# nrf9230_enga_sysctrl register map
Vendor: Nordic Semiconductor; Series: nRF92; File version: 1
Registers are 32-bit, read-write, reset 0x0 unless marked. A register's access mark holds for its fields unless they carry their own. Offsets are from the block's base; [hi:lo] are bit positions; lines under a group give offsets from that group; {n}, {i} and the like mark numbered series; 'fields as' and 'values as' point back to an identical list.

## GLOBAL_EGU130 — Event generator unit
Base 0x5F92D000
{0x0+4i} TASKS_TRIGGER[{i}] (i=0..15) wo — Description collection: Trigger n for triggering the corresponding TRIGGERED[n] event
  [0] TASKS_TRIGGER — Trigger n for triggering the corresponding TRIGGERED[n] event
    1=Trigger task
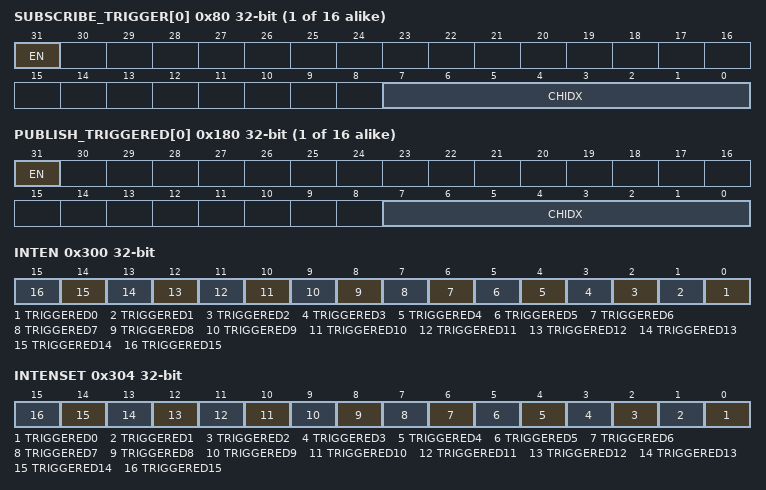
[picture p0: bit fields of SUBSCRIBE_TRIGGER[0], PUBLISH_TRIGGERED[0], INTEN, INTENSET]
{0x80+4i} SUBSCRIBE_TRIGGER[{i}] (i=0..15) — Description collection: Subscribe configuration for task TRIGGER[n]
  [31] EN
    0=Disabled (Disable subscription); 1=Enabled (Enable subscription)
  [7:0] CHIDX — DPPI channel that task TRIGGER[n] will subscribe to
{0x100+4i} EVENTS_TRIGGERED[{i}] (i=0..15) — Description collection: Event number n generated by triggering the corresponding TRIGGER[n] task
  [0] EVENTS_TRIGGERED — Event number n generated by triggering the corresponding TRIGGER[n] task
    0=NotGenerated (Event not generated); 1=Generated (Event generated)
{0x180+4i} PUBLISH_TRIGGERED[{i}] (i=0..15) — Description collection: Publish configuration for event TRIGGERED[n]
  [31] EN
    0=Disabled (Disable publishing); 1=Enabled (Enable publishing)
  [7:0] CHIDX — DPPI channel that event TRIGGERED[n] will publish to
0x300 INTEN — Enable or disable interrupt
  [all] fields
    0=Disabled; 1=Enabled
  [n] TRIGGERED{n} (n=0..15) — Enable or disable interrupt for event TRIGGERED[{n}]
0x304 INTENSET — Enable interrupt
  [all] fields
    on read: 0=Disabled (Read: Disabled); 1=Enabled (Read: Enabled) | on write: 1=Set (Enable)
  [n] TRIGGERED{n} (n=0..15) — Write '1' to enable interrupt for event TRIGGERED[{n}]
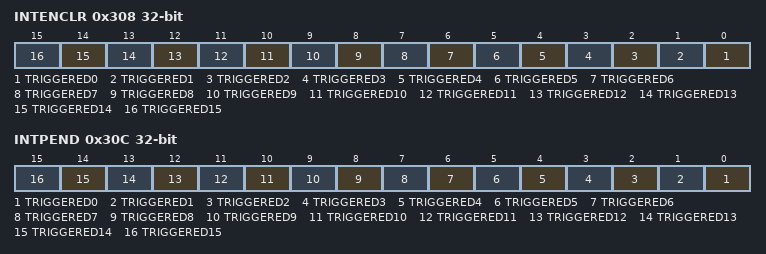
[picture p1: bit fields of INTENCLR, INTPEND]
0x308 INTENCLR — Disable interrupt
  [all] fields
    on read: 0=Disabled (Read: Disabled); 1=Enabled (Read: Enabled) | on write: 1=Clear (Disable)
  [n] TRIGGERED{n} (n=0..15) — Write '1' to disable interrupt for event TRIGGERED[{n}]
0x30C INTPEND ro — Pending interrupts
  [all] fields
    on read: 0=NotPending (Read: Not pending); 1=Pending (Read: Pending)
  [n] TRIGGERED{n} (n=0..15) — Read pending status of interrupt for event TRIGGERED[{n}]

## GLOBAL_GPIOINTERNAL — GPIO Internal
Base 0x5F939E00
0x40 LATCHCLRWAITCNT reset 0x2 — Select the number of wait cycles inserted on the bus when a LATCH register is cleared.
  [1:0] LATCHCLRWAITCNT
0x44 FORCELDETECTLOWCNT reset 0x8 — Select the number of cycles that LDETECT is forced low after clearing a LATCH register.
  [3:0] FORCELDETECTLOWCNT
0x48 RESET — Reset all GPIO registers.
  [0] RESET
    1=RESET (Trigger reset); 0=NA (No effect)
0x4C SENSECONFIGCHANGECNT reset 0x3 — Selects the number of cycles before the SENSE configuration takes effect when it is changed. Setting this register lower than the reset value can lead to unwanted LATCH set when SENSE and INPUT fields (PIN[n].CNF) are changed simultaneously.
  [2:0] SENSECONFIGCHANGECNT — Selects the number of cycles before the SENSE configuration takes effect when it is changed.
0x160 PCGC group — Unspecified
  0x00 TURNOFFAUTOCLOCKSOURCEREQ ro — No functionality
  {0x20+4j} PENALTY[{j}] (j=0..4) ro — Description collection: Penalty level for power/clock pair n
    [7:0] PENALTY — Penalty level
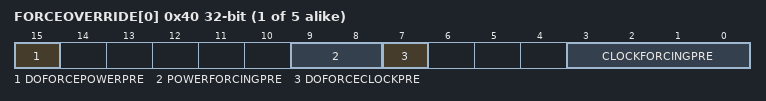
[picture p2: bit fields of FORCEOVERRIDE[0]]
  {0x40+4j} FORCEOVERRIDE[{j}] (j=0..4) ro — Description collection: Force override of power/clock pair n
    [15] DOFORCEPOWERPRE, [9:8] POWERFORCINGPRE, [7] DOFORCECLOCKPRE, [3:0] CLOCKFORCINGPRE

## OSCRFR — OSCRFR peripheral
Base 0x5F96B000
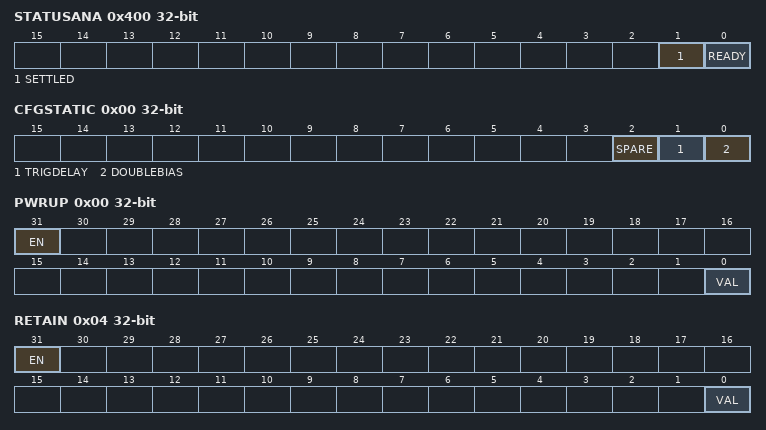
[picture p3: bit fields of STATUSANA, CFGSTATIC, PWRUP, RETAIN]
0x400 STATUSANA ro — Status of analog module output signals
  [1] SETTLED — Current value of the SETTLED signal from the analog module
  [0] READY — Current value of the READY signal from the analog module
0x410 CONFIG group — Unspecified
  0x00 CFGSTATIC — OSCRFR static CFG configuration
    [2] SPARE
    [1] TRIGDELAY — Increase TRIG signal delay
      0=Disabled; 1=Enabled
    [0] DOUBLEBIAS — Enable double bias
      0=Disabled; 1=Enabled
0x440 TRIM group — Unspecified
  0x00 OSC — Oscillation period trimming
    [2:0] VAL — Oscillation period trimming value
      0=Normal trim value; 1=The trim value is 35 percent; 2=The trim value is 154 percent; 3=The trim value is 670 percent; 4=ValNeg51 (The trim value is -54 percent); 5=ValNeg42 (The trim value is -49 percent); 6=ValNeg31 (The trim value is -37 percent); 7=ValNeg18 (The trim value is -26 percent)
  0x04 IBPSR — IBPSR current trimming
    [3:0] VAL — IBPSR current and VREF voltage trimming value
0x480 MIRROR reset 0x1 — Enable LOCK for mirrored registers
  [0] LOCK — Lock for mirrored registers
    0=Disabled (Lock disabled); 1=Enabled (Lock enabled)
0x484 MODE — Oscillator mode
  [0] MODE
    0=Normal mode - Use internal oscillator; 1=Bypass mode - Use OSC_RFR_DIG_AO_0V8 signal
0x500 OVERRIDE group — Unspecified
  0x00 PWRUP — Override the PWRUP signal to the analog module
    [31] EN — Enable the override
      0=Disabled (Override is disabled); 1=Enabled (Override is enabled)
    [0] VAL — Override value for the signal
  0x04 RETAIN — Override the RETAIN signal to the analog module
    fields as OVERRIDE.PWRUP
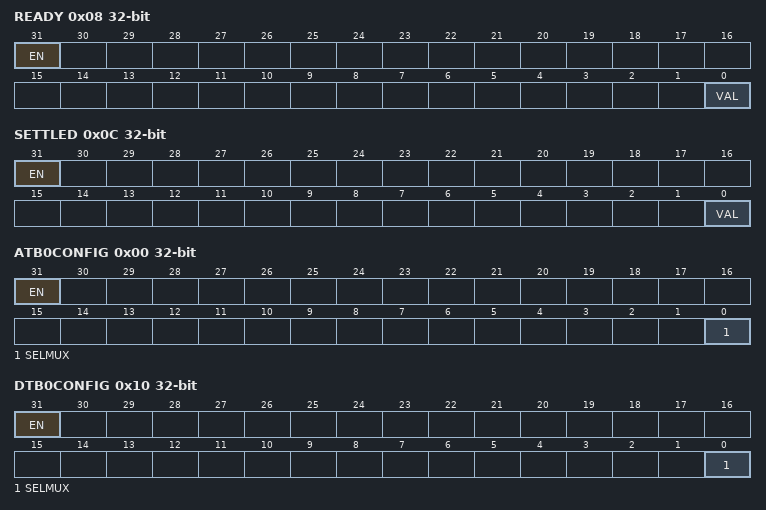
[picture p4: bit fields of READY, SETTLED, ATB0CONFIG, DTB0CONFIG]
  0x08 READY — Override the READY signal from the analog module
    [31] EN — Enable the override
      values as OVERRIDE.PWRUP.EN
    [0] VAL — Current value of the signal
  0x0C SETTLED — Override the SETTLED signal from the analog module
    fields as OVERRIDE.READY
0x600 DFT group — Unspecified
  0x00 ATB0CONFIG — Analog Test Bus 0 (ATB0) configuration
    [31] EN — Enable the analog test bus
      0=Disabled (Analog test bus is disabled); 1=Enabled (Analog test bus is enabled)
    [0] SELMUX — Select multiplexer for ATB0
      0=IBPSR4U (IBPSR_4U signal selected); 1=IBPP50N (IBPP_50N signal selected)
  0x10 DTB0CONFIG — Digital Test Bus 0 (DTB0) configuration
    [31] EN — Enable the digital test bus
      0=Disabled (Digital test bus is disabled); 1=Enabled (Digital test bus is enabled)
    [0] SELMUX — Select multiplexer for DTB0
      0=READY (READY signal selected); 1=OSC (OSC_RFR_ANA_AO_0V8 signal selected)
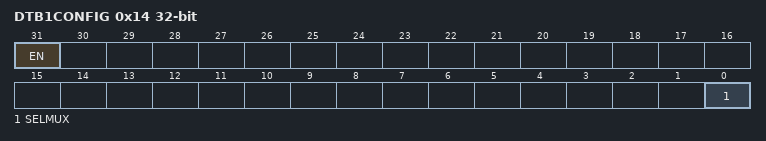
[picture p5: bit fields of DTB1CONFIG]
  0x14 DTB1CONFIG — Digital Test Bus 1 (DTB1) configuration
    [31] EN — Enable the digital test bus
      values as DFT.DTB0CONFIG.EN
    [0] SELMUX — Select multiplexer for DTB1
      0=SETTLED (SETTLED signal selected); 1=OSC (OSC_RFR_ANA_AO_0V8 signal selected)
  0x1C DTB3CONFIG — Digital Test Bus 3 (DTB3) configuration
    [27] PWRUPDELTEST — Enable the PWRUP delay test circuit
      0=Disabled (PWRUP delay test circuit is disabled); 1=Enabled (PWRUP delay test circuit is enabled)
  0x30 TCFG — Test mode configuration
    [0] BIASCURRENT — Enable continuous mode for measuring bias current over ATB
      0=Disabled; 1=Enabled

## VDETIO — VDETIO peripheral
Base 0x5F974000
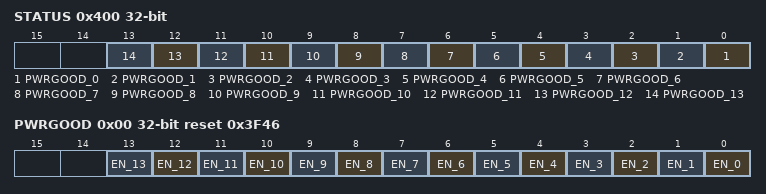
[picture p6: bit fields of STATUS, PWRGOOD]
0x400 STATUS ro — Voltage detector status
  [all] fields
    0=AboveThr (Power good detector detected voltage above threshold level); 1=BelowThr (Power good detector detected voltage below threshold level)
  [n] PWRGOOD_{n} (n=0..13) — Power good detector status for port [{n}]
0x410 CONFIG group — Unspecified
  0x00 PWRGOOD reset 0x3F46 — Power good detector configuration
    [all] fields
      0=Disabled (IO voltage detector is disabled); 1=Enabled (IO voltage detector is enabled)
    [n] EN_{n} (n=0..13) — Enable the power good detector for port [{n}]

## VSPOWERC — VSPOWERC peripheral
Base 0x5F977000
{0x410+8i} CONFIG[{i}] (i=0..1) group — Unspecified
  0x00 PWRSRC — Description cluster: Power source select for dual power switch domain [n]
    [0] SRC — Selecting between VS and AO power
      0=SelVS (Voltage scaled VDD_VS_0V8); 1=SelAO (Always-on VDD_AO_0V8)
  0x04 OVERLAP — Description cluster: Configuration of switch control overlap time for dual power switch domain [n]
    [3:0] VAL — Overlap time, both power requests active
{0x500+4i} OVERRIDE[{i}] (i=0..1) group — Unspecified
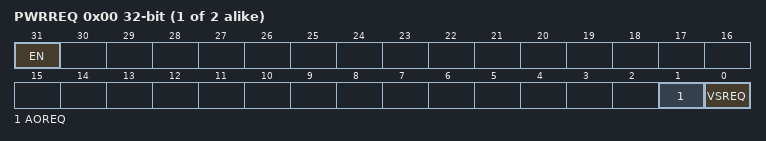
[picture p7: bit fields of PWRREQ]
  0x00 PWRREQ — Description cluster: Override the power requests for dual power switch domain [n]
    [31] EN — Enable the override
      0=Disabled (Override is disabled); 1=Enabled (Override is enabled)
    [1] AOREQ — Override value for the VDD_AO_0V8 power request
    [0] VSREQ — Override value for the VDD_VS_0V8 power request

## PMICC — PMIC Controller
Base 0x5F978000
0x100 EVENTS_FPWMRDYHI — PMIC fPwmRdy went from low to high.
  [0] EVENTS_FPWMRDYHI
    0=NotGenerated (Event not generated); 1=Generated (Event generated)
0x104 EVENTS_FPWMRDYLO — PMIC fPwmRdy went from high to low.
  [0] EVENTS_FPWMRDYLO
    values as EVENTS_FPWMRDYHI.EVENTS_FPWMRDYHI
{0x108+4i} EVENTS_CURRABOVE[{i}] (i=0..2) — Description collection: Current consumption went above the threshold for source n.
  [0] EVENTS_CURRABOVE — Current consumption went above the threshold for source n.
    values as EVENTS_FPWMRDYHI.EVENTS_FPWMRDYHI
{0x114+4i} EVENTS_CURRBELOW[{i}] (i=0..2) — Description collection: Current consumption went below the threshold for source n.
  [0] EVENTS_CURRBELOW — Current consumption went below the threshold for source n.
    values as EVENTS_FPWMRDYHI.EVENTS_FPWMRDYHI
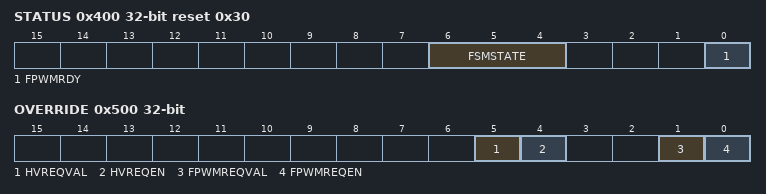
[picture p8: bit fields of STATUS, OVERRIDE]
0x400 STATUS ro reset 0x30 — PMICC Status
  [6:4] FSMSTATE — State machine state
    0=DISABLED (PMICC has been disabled); 1=ULP (ULP or HV_REQ state); 2=PGDREQ (PGD_REQ state); 3=BODHPREQ (BOD_HP_REQ state); 4=HV (HV state); 5=PWMREQ (PWM_REQ state); 6=PWM (PWM state); 7=BODULPREQ (BOD_ULP_REQ state)
  [0] FPWMRDY — State of PMIC fPwmRdy signal
    0=ZERO (fPwmRdy low); 1=ONE (fPwmRdy high)
0x404 ITHRESHOLD reset 0x32 — Current threshold
  [5:0] THRES
0x500 OVERRIDE — Override request outputs
  [5] HVREQVAL — Value to force PMIC HVReq to
  [4] HVREQEN — Whether to force PMIC HVReq
    0=DISABLE (Not forcing HVReq); 1=ENABLE (Forcing HVReq to value in HVREQVAL)
  [1] FPWMREQVAL — Value to force PMIC fPwmReq to
  [0] FPWMREQEN — Whether to force PMIC fPwmReq
    0=DISABLE (Not forcing fPwmReq); 1=ENABLE (Forcing fPwmReq to value in FPWMREQVAL)
